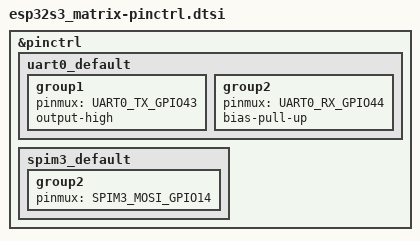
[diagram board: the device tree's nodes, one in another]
/*
 * Copyright (c) 2024 Espressif Systems (Shanghai) Co., Ltd.
 *
 * SPDX-License-Identifier: Apache-2.0
 */

#include <zephyr/dt-bindings/pinctrl/esp-pinctrl-common.h>
#include <dt-bindings/pinctrl/esp32s3-pinctrl.h>
#include <zephyr/dt-bindings/pinctrl/esp32s3-gpio-sigmap.h>

&pinctrl {
	uart0_default: uart0_default {
		group1 {
			pinmux = <UART0_TX_GPIO43>;
			output-high;
		};
		group2 {
			pinmux = <UART0_RX_GPIO44>;
			bias-pull-up;
		};
	};

	spim3_default: spim3_default {
		group2 {
			pinmux = <SPIM3_MOSI_GPIO14>;
		};
	};
};
